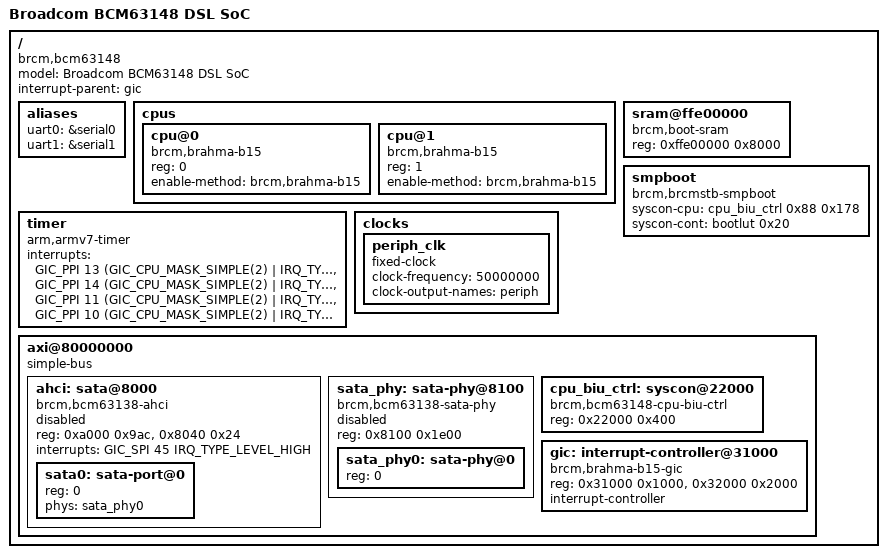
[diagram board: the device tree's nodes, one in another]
// SPDX-License-Identifier: GPL-2.0
/*
 * Broadcom BCM63148 DSL SoCs Device Tree
 */

#include <dt-bindings/interrupt-controller/arm-gic.h>
#include <dt-bindings/interrupt-controller/irq.h>

#include "bcm631x8-ubus.dtsi"

/ {
	compatible = "brcm,bcm63148";
	model = "Broadcom BCM63148 DSL SoC";
	interrupt-parent = <&gic>;

	aliases {
		uart0 = &serial0;
		uart1 = &serial1;
	};

	cpus {
		#address-cells = <1>;
		#size-cells = <0>;

		cpu@0 {
			device_type = "cpu";
			compatible = "brcm,brahma-b15";
			reg = <0>;
			enable-method = "brcm,brahma-b15";
		};

		cpu@1 {
			device_type = "cpu";
			compatible = "brcm,brahma-b15";
			reg = <1>;
			enable-method = "brcm,brahma-b15";
		};
	};

	timer {
		compatible = "arm,armv7-timer";
		interrupts = <GIC_PPI 13 (GIC_CPU_MASK_SIMPLE(2) |
					  IRQ_TYPE_LEVEL_LOW)>,
			     <GIC_PPI 14 (GIC_CPU_MASK_SIMPLE(2) |
					  IRQ_TYPE_LEVEL_LOW)>,
			     <GIC_PPI 11 (GIC_CPU_MASK_SIMPLE(2) |
					  IRQ_TYPE_LEVEL_LOW)>,
			     <GIC_PPI 10 (GIC_CPU_MASK_SIMPLE(2) |
					  IRQ_TYPE_LEVEL_LOW)>;
	};

	sram@ffe00000 {
		compatible = "brcm,boot-sram", "mmio-sram";
		reg = <0xffe00000 0x8000>;
	};

	smpboot {
		compatible = "brcm,brcmstb-smpboot";
		syscon-cpu = <&cpu_biu_ctrl 0x88 0x178>;
		syscon-cont = <&bootlut 0x20>;
	};

	clocks {
		#address-cells = <1>;
		#size-cells = <0>;

		/* UBUS peripheral clock */
		periph_clk: periph_clk {
			#clock-cells = <0>;
			compatible = "fixed-clock";
			clock-frequency = <50000000>;
			clock-output-names = "periph";
		};
	};

	/* ARM bus */
	axi@80000000 {
		compatible = "simple-bus";
		ranges = <0 0x80000000 0x784000>;
		#address-cells = <1>;
		#size-cells = <1>;

		ahci: sata@8000 {
			compatible = "brcm,bcm63138-ahci", "brcm,sata3-ahci";
			reg-names = "ahci", "top-ctrl";
			reg = <0xa000 0x9ac>, <0x8040 0x24>;
			interrupts = <GIC_SPI 45 IRQ_TYPE_LEVEL_HIGH>;
			#address-cells = <1>;
			#size-cells = <0>;
			status = "disabled";

			sata0: sata-port@0 {
				reg = <0>;
				phys = <&sata_phy0>;
			};
		};

		sata_phy: sata-phy@8100 {
			compatible = "brcm,bcm63138-sata-phy", "brcm,phy-sata3";
			reg = <0x8100 0x1e00>;
			reg-names = "phy";
			#address-cells = <1>;
			#size-cells = <0>;
			status = "disabled";

			sata_phy0: sata-phy@0 {
				reg = <0>;
				#phy-cells = <0>;
			};
		};

		cpu_biu_ctrl: syscon@22000 {
			compatible = "brcm,bcm63148-cpu-biu-ctrl",
				     "brcm,brcmstb-cpu-biu-ctrl",
				     "syscon";
			reg = <0x22000 0x400>;
		};

		gic: interrupt-controller@31000 {
			compatible = "brcm,brahma-b15-gic",
				     "arm,cortex-a15-gic";
			reg = <0x31000 0x1000>,
			      <0x32000 0x2000>;
			reg-names = "dist",
				    "cpu";
			interrupt-controller;
			#interrupt-cells = <3>;
		};
	};
};
